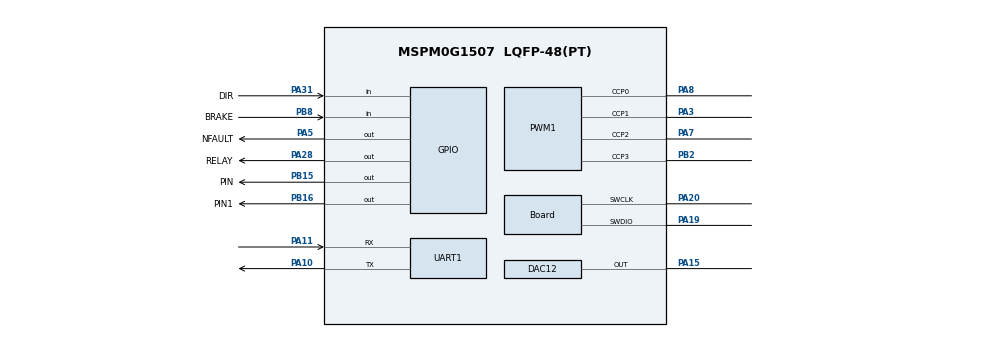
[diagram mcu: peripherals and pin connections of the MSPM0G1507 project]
//@cliArgs --device "MSPM0G150X" --package "LQFP-48(PT)" --part "Default"
//@v2CliArgs --device "MSPM0G1507" --package "LQFP-48(PT)"
// @cliArgs --board /ti/boards/LP_MSPM0G3507 --rtos nortos

/**
 * Import the modules used in this configuration.
 */
const ADC12         = scripting.addModule("/ti/driverlib/ADC12", {}, false);
const ADC121        = ADC12.addInstance();
const ADC122        = ADC12.addInstance();
const Board         = scripting.addModule("/ti/driverlib/Board");
const CAPTURE       = scripting.addModule("/ti/driverlib/CAPTURE", {}, false);
const CAPTURE1      = CAPTURE.addInstance();
const CRC           = scripting.addModule("/ti/driverlib/CRC");
const DAC12         = scripting.addModule("/ti/driverlib/DAC12");
const GPIO          = scripting.addModule("/ti/driverlib/GPIO", {}, false);
const GPIO1         = GPIO.addInstance();
const GPIO2         = GPIO.addInstance();
const GPIO3         = GPIO.addInstance();
const MATHACL       = scripting.addModule("/ti/driverlib/MATHACL");
const PWM           = scripting.addModule("/ti/driverlib/PWM", {}, false);
const PWM1          = PWM.addInstance();
const SYSCTL        = scripting.addModule("/ti/driverlib/SYSCTL");
const TIMER         = scripting.addModule("/ti/driverlib/TIMER", {}, false);
const TIMER1        = TIMER.addInstance();
const TIMERFault    = scripting.addModule("/ti/driverlib/TIMERFault", {}, false);
const TIMERFault1   = TIMERFault.addInstance();
const UART          = scripting.addModule("/ti/driverlib/UART", {}, false);
const UART1         = UART.addInstance();
const ProjectConfig = scripting.addModule("/ti/project_config/ProjectConfig");

/**
 * Write custom configuration values to the imported modules.
 */
ProjectConfig.genDisable = true;

ADC121.$name                      = "ADC0";
ADC121.sampClkSrc                 = "DL_ADC12_CLOCK_ULPCLK";
ADC121.samplingOperationMode      = "sequence";
ADC121.repeatMode                 = true;
ADC121.trigSrc                    = "DL_ADC12_TRIG_SRC_EVENT";
ADC121.powerDownMode              = "DL_ADC12_POWER_DOWN_MODE_MANUAL";
ADC121.adcMem3trig                = "DL_ADC12_TRIGGER_MODE_TRIGGER_NEXT";
ADC121.enabledInterrupts          = ["DL_ADC12_INTERRUPT_MEM2_RESULT_LOADED"];
ADC121.interruptPriority          = "1";
ADC121.adcMem3chansel             = "DL_ADC12_INPUT_CHAN_1";
ADC121.adcMem0chansel             = "DL_ADC12_INPUT_CHAN_2";
ADC121.adcMem1chansel             = "DL_ADC12_INPUT_CHAN_3";
ADC121.adcMem2chansel             = "DL_ADC12_INPUT_CHAN_5";
ADC121.endAdd                     = 3;
ADC121.subChanID                  = 12;
ADC121.adcMem0avgen               = true;
ADC121.adcMem1avgen               = true;
ADC121.adcMem2avgen               = true;
ADC121.adcMem3avgen               = true;
ADC121.sampleTime0                = "250ns";
ADC121.sampleTime1                = "250ns";
ADC121.hwNumerator                = "DL_ADC12_HW_AVG_NUM_ACC_4";
ADC121.hwDenominator              = "DL_ADC12_HW_AVG_DEN_DIV_BY_4";
ADC121.peripheral.$assign         = "ADC0";
ADC121.peripheral.adcPin1.$assign = "PA26";
ADC121.peripheral.adcPin2.$assign = "PA25";
ADC121.peripheral.adcPin3.$assign = "PA24";
ADC121.peripheral.adcPin5.$assign = "PB24";

ADC122.$name                      = "ADC1";
ADC122.sampClkSrc                 = "DL_ADC12_CLOCK_ULPCLK";
ADC122.samplingOperationMode      = "sequence";
ADC122.repeatMode                 = true;
ADC122.trigSrc                    = "DL_ADC12_TRIG_SRC_EVENT";
ADC122.endAdd                     = 2;
ADC122.subChanID                  = 12;
ADC122.adcMem2trig                = "DL_ADC12_TRIGGER_MODE_TRIGGER_NEXT";
ADC122.powerDownMode              = "DL_ADC12_POWER_DOWN_MODE_MANUAL";
ADC122.adcMem0chansel             = "DL_ADC12_INPUT_CHAN_6";
ADC122.adcMem1chansel             = "DL_ADC12_INPUT_CHAN_5";
ADC122.adcMem2chansel             = "DL_ADC12_INPUT_CHAN_4";
ADC122.adcMem0avgen               = true;
ADC122.adcMem1avgen               = true;
ADC122.adcMem2avgen               = true;
ADC122.sampleTime0                = "250ns";
ADC122.sampleTime1                = "250ns";
ADC122.hwNumerator                = "DL_ADC12_HW_AVG_NUM_ACC_4";
ADC122.hwDenominator              = "DL_ADC12_HW_AVG_DEN_DIV_BY_4";
ADC122.peripheral.$assign         = "ADC1";
ADC122.peripheral.adcPin6.$assign = "PB19";
ADC122.peripheral.adcPin5.$assign = "PB18";
ADC122.peripheral.adcPin4.$assign = "PB17";

Board.peripheral.$assign          = "DEBUGSS";
Board.peripheral.swclkPin.$assign = "PA20";
Board.peripheral.swdioPin.$assign = "PA19";

CAPTURE1.timerStartTimer      = true;
CAPTURE1.captSelect           = "Trigger";
CAPTURE1.subscriberPort       = "FSUB0";
CAPTURE1.multi_ch0_input_mode = "DL_TIMER_CC_IN_SEL_FSUB0";
CAPTURE1.multi_ch_zero        = 0;
CAPTURE1.ccIndexMulti         = [0];
CAPTURE1.subscriberChannel    = 13;
CAPTURE1.timerPeriod          = "800us";
CAPTURE1.$name                = "CAPTURE";
CAPTURE1.interrupts           = ["CC0_DN","ZERO"];
CAPTURE1.peripheral.$assign   = "TIMA1";

CRC.polynomial = "16_POLYNOMIAL";
CRC.seed       = 0xFFFF;

DAC12.dacOutputPinEn            = true;
DAC12.dacSampleTimerEn          = true;
DAC12.dacSampleTimerRate        = "100K";
DAC12.dacAmplifier              = "ON";
DAC12.peripheral.$assign        = "DAC0";
DAC12.peripheral.OutPin.$assign = "PA15";

GPIO1.$name                              = "FOC_GPIO_OUT";
GPIO1.associatedPins.create(2);
GPIO1.associatedPins[0].$name            = "NFAULT";
GPIO1.associatedPins[0].internalResistor = "PULL_UP";
GPIO1.associatedPins[0].pin.$assign      = "PA5";
GPIO1.associatedPins[1].$name            = "RELAY";
GPIO1.associatedPins[1].pin.$assign      = "PA28";

GPIO2.$name                         = "FOC_GPIO_IN";
GPIO2.associatedPins.create(2);
GPIO2.associatedPins[0].$name       = "DIR";
GPIO2.associatedPins[0].direction   = "INPUT";
GPIO2.associatedPins[0].pin.$assign = "PA31";
GPIO2.associatedPins[1].direction   = "INPUT";
GPIO2.associatedPins[1].$name       = "BRAKE";
GPIO2.associatedPins[1].pin.$assign = "PB8";

GPIO3.$name                             = "TST";
GPIO3.associatedPins.create(2);
GPIO3.associatedPins[0].$name           = "PIN";
GPIO3.associatedPins[0].pin.$assign     = "PB15";
GPIO3.associatedPins[1].$name           = "PIN1";
GPIO3.associatedPins[1].subOutputPolicy = "TOGGLE";
GPIO3.associatedPins[1].subChanID       = 1;
GPIO3.associatedPins[1].pin.$assign     = "PB16";

PWM1.pwmMode                                 = "CENTER_ALIGN";
PWM1.deadBandEn                              = true;
PWM1.dbRiseDelayTimerCount                   = 32;
PWM1.dbFallDelayTimerCount                   = 32;
PWM1.dbInsertionMode                         = "Mode0";
PWM1.ccIndexCmpl                             = [0,1,3];
PWM1.enableShadowLoad                        = true;
PWM1.timerStartTimer                         = true;
PWM1.faultHandlerEn                          = true;
PWM1.faultConditionDuration                  = "FL_LATCH_SW_CLR";
PWM1.faultInput                              = "FI_DEPENDENT";
PWM1.faultInputEn                            = "FIEN_ENABLED";
PWM1.faultInputFilterEn                      = true;
PWM1.faultChannel1BehaviorEntry              = "LOW";
PWM1.faultChannel1BehaviorExit               = "LOW";
PWM1.faultChannel2BehaviorEntry              = "LOW";
PWM1.faultChannel2BehaviorExit               = "LOW";
PWM1.faultChannel3BehaviorEntry              = "LOW";
PWM1.faultChannel3BehaviorExit               = "LOW";
PWM1.faultInputDetect                        = true;
PWM1.faultFilterSamplePeriod                 = "8";
PWM1.event1PublisherChannel                  = 12;
PWM1.ccIndex                                 = [0,1,2,3];
PWM1.timerCount                              = 8000;
PWM1.enableRepeatCounter                     = true;
PWM1.faultChannel0BehaviorEntry              = "LOW";
PWM1.faultChannel0BehaviorExit               = "LOW";
PWM1.$name                                   = "PWMA0";
PWM1.faultTimerCountExit                     = "FAULT_EXIT_CTR_CVAE_ACTION";
PWM1.event1ControllerInterruptEn             = ["CC2_DN_EVENT"];
PWM1.event2ControllerInterruptEn             = ["CC2_DN_EVENT"];
PWM1.faultSource                             = ["1"];
PWM1.subscriberPort                          = "FSUB0";
PWM1.subscriberChannel                       = 13;
PWM1.event2PublisherChannel                  = 1;
PWM1.peripheral.$assign                      = "TIMA0";
PWM1.peripheral.ccp0Pin.$assign              = "PA8";
PWM1.peripheral.ccp1Pin.$assign              = "PA3";
PWM1.peripheral.ccp0Pin_cmpl.$assign         = "PA9";
PWM1.peripheral.ccp1Pin_cmpl.$assign         = "PA4";
PWM1.peripheral.ccp2Pin.$assign              = "PA7";
PWM1.peripheral.ccp3Pin.$assign              = "PB2";
PWM1.peripheral.ccp3Pin_cmpl.$assign         = "PB3";
PWM1.PWM_CHANNEL_0.$name                     = "ti_driverlib_pwm_PWMTimerCC1";
PWM1.PWM_CHANNEL_0.shadowUpdateMode          = "ZERO_EVT";
PWM1.PWM_CHANNEL_1.$name                     = "ti_driverlib_pwm_PWMTimerCC2";
PWM1.PWM_CHANNEL_1.shadowUpdateMode          = "ZERO_EVT";
PWM1.PWM_CHANNEL_2.$name                     = "ti_driverlib_pwm_PWMTimerCC6";
PWM1.PWM_CHANNEL_3.$name                     = "ti_driverlib_pwm_PWMTimerCC0";
PWM1.PWM_CHANNEL_3.shadowUpdateMode          = "ZERO_EVT";

SYSCTL.SYSPLL_CLK2XEn     = true;
SYSCTL.SYSPLL_Pdiv        = 1;
SYSCTL.SYSPLL_Qdiv        = 5;
SYSCTL.SYSPLL_CLK2XDiv    = 3;
SYSCTL.MCLKSource         = "HSCLK";
SYSCTL.HSCLKSource        = "SYSPLLCLK2X";
SYSCTL.validateClkStatus  = true;
SYSCTL.MFPCLKEn           = true;
SYSCTL.UDIV               = "2";
SYSCTL.peripheral.$assign = "SYSCTL";

TIMER1.$name              = "FOC_TIMG0";
TIMER1.timerPeriod        = "1 ms";
TIMER1.timerMode          = "PERIODIC";
TIMER1.timerStartTimer    = true;
TIMER1.interrupts         = ["LOAD"];
TIMER1.peripheral.$assign = "TIMG0";

PWM1.associatedFault              = TIMERFault1;
TIMERFault1.$name                 = "FOC_TIM_FAULT";
TIMERFault1.enabledFaults         = ["1"];
TIMERFault1.faultPin1.$assign     = "PB20";

UART1.$name                               = "UART_0";
UART1.targetBaudRate                      = 115200;
UART1.enableFIFO                          = true;
UART1.rxFifoThreshold                     = "DL_UART_RX_FIFO_LEVEL_ONE_ENTRY";
UART1.txFifoThreshold                     = "DL_UART_TX_FIFO_LEVEL_EMPTY";
UART1.enabledDMATXTriggers                = "DL_UART_DMA_INTERRUPT_TX";
UART1.enabledDMARXTriggers                = "DL_UART_DMA_INTERRUPT_RX";
UART1.peripheral.$assign                  = "UART0";
UART1.peripheral.rxPin.$assign            = "PA11";
UART1.peripheral.txPin.$assign            = "PA10";
UART1.DMA_CHANNEL_TX.$name                = "DMA_CH1";
UART1.DMA_CHANNEL_TX.addressMode          = "b2f";
UART1.DMA_CHANNEL_TX.srcLength            = "BYTE";
UART1.DMA_CHANNEL_TX.dstLength            = "BYTE";
UART1.DMA_CHANNEL_TX.srcIncrement         = "INCREMENT";
UART1.DMA_CHANNEL_TX.enableInterrupt      = true;
UART1.DMA_CHANNEL_TX.peripheral.$assign   = "DMA_CH1";
UART1.DMA_CHANNEL_RX.$name                = "DMA_CH0";
UART1.DMA_CHANNEL_RX.addressMode          = "f2b";
UART1.DMA_CHANNEL_RX.srcLength            = "BYTE";
UART1.DMA_CHANNEL_RX.dstLength            = "BYTE";
UART1.DMA_CHANNEL_RX.destIncrement        = "INCREMENT";
UART1.DMA_CHANNEL_RX.enableEarlyInterrupt = true;
UART1.DMA_CHANNEL_RX.earlyIntThresh       = "64";
UART1.DMA_CHANNEL_RX.peripheral.$assign   = "DMA_CH0";
